# FIXTURE register map
File version: 1.0
Device exercising what the generated headers promise
CPU: CM33 r0p0, little endian, MPU, no FPU, 3 interrupt priority bits
Registers are 32-bit, access not given, no defined reset value unless marked. A register's access mark holds for its fields unless they carry their own. Offsets are from the block's base; lines under a group give offsets from that group; [hi:lo] are bit positions; {n}, {i} and the like mark numbered series; 'fields as' and 'values as' point back to an identical list; <NAME> marks a mode.

## Memory map
0x40001000 CTL — Control block: fields of every width and access
0x40002000 PORTA
0x40002400 PORTB — Port B: same registers as port A under its own names, another reset value
0x40002800 PORTC
0x40003000 DMA1 — DMA controller: channels as numbered registers, the last one with one more register
0x40004000 BANK — SVD cluster array, a register array and overlapping registers

## Interrupts
2 CTL — Control interrupt
5 CTL_ERR (CTL) — Control error interrupt
8 DMA1_CH0 (DMA1) — Channel 0 interrupt

## CTL — Control block: fields of every width and access
Base 0x40001000
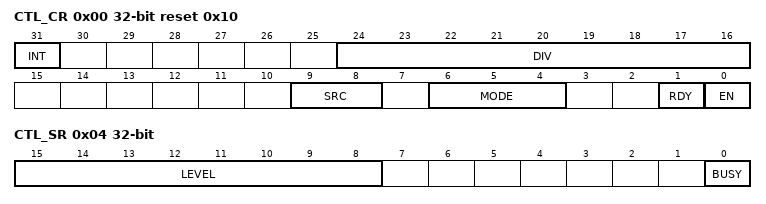
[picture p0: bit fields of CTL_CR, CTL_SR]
0x00 CTL_CR access per field reset 0x10 — Control register
  [31] INT rw — Field named like a keyword
  [24:16] DIV rw — Divider
  [9:8] SRC rw — Clock source
    0=Internal oscillator; 1=External oscillator
  [6:4] MODE rw — Operating mode
    0=Off (Stopped); 1=Slow (Low-power run); 5=Fast (Full-speed run)
  [1] RDY ro — Ready, set by hardware
  [0] EN rw — Enable
0x04 CTL_SR ro — Status register: every field is read-only
  [15:8] LEVEL — Fill level
  [0] BUSY
0x08 CTL_ICR wo — Interrupt clear register: every field is write-only
  [0] CBUSY — Clear busy
0x10 CTL_DATA — Data register without fields
0x14 CTL_SMALL 8-bit — 8-bit register
  [7:4] NIB — Nibble

## PORTA
Base 0x40002000
Same registers: PORTC 0x40002800
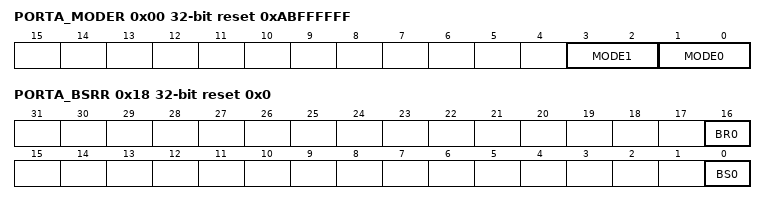
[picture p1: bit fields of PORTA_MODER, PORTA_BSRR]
0x00 PORTA_MODER reset 0xABFFFFFF — Mode register
  [3:2] MODE1 — Mode of pin 1
  [1:0] MODE0 — Mode of pin 0
0x18 PORTA_BSRR wo reset 0x0 — Bit set/reset register
  [16] BR0 — Reset pin 0
  [0] BS0 — Set pin 0

## PORTB — Port B: same registers as port A under its own names, another reset value
Base 0x40002400
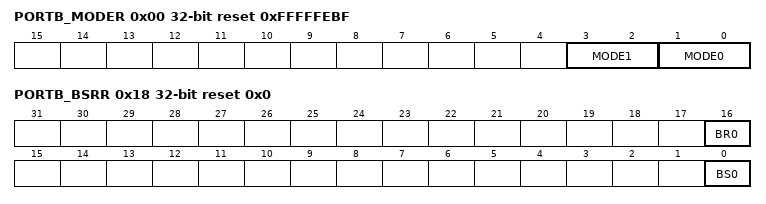
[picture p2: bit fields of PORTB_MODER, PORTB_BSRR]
0x00 PORTB_MODER reset 0xFFFFFEBF — Mode register
  [3:2] MODE1 — Mode of pin 1
  [1:0] MODE0 — Mode of pin 0
0x18 PORTB_BSRR wo reset 0x0 — Bit set/reset register
  [16] BR0 — Reset pin 0
  [0] BS0 — Set pin 0

## DMA1 — DMA controller: channels as numbered registers, the last one with one more register
Base 0x40003000
0x00 DMA_ISR ro — Interrupt status
  [0] TC0 — Transfer complete 0
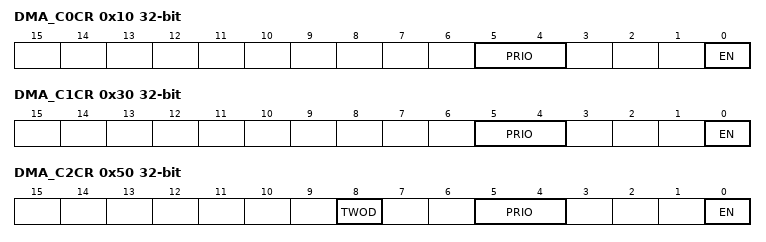
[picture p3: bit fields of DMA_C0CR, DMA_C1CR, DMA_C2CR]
0x10 DMA_C0CR — Channel 0 control
  [5:4] PRIO — Priority
  [0] EN — Enable
{0x14+0x20*i} DMA_C{i}SAR (i=0..2) — Channel {i} source address
  [31:0] SA — Source address
0x30 DMA_C1CR — Channel 1 control
  [5:4] PRIO — Priority
  [0] EN — Enable
0x50 DMA_C2CR — Channel 2 control
  [8] TWOD — 2D addressing, last channel only
  [5:4] PRIO — Priority
  [0] EN — Enable
0x58 DMA_C2TR3 — Channel 2 2D offsets, last channel only
  [12:0] SAO — Source address offset

## BANK — SVD cluster array, a register array and overlapping registers
Base 0x40004000
{0x0+0x10*i} SLOT[{i}] (i=0..2) group — One slot
  0x00 CFG — Slot configuration
    [0] ON — Slot on
  0x08 CNT 16-bit — Slot counter
    [15:0] CNT — Count
{0x40+4i} KEY[{i}] (i=0..3) — Key word
  [31:0] K — Key
0x50 WORD — Word view
  [31:0] W — Word
0x50 BYTE0 8-bit — Byte view of the word, first byte
  [7:0] B — Byte
0x51 BYTE1 8-bit — Byte view of the word, second byte
  [7:0] B — Byte
